# PIC32MZ2064DAS176 device description
Architecture: MIPS; Family: PIC32MZDA; Series: PIC32MZ
Registers are 32-bit, read-write, no defined reset value unless marked. A register's access mark holds for its fields unless they carry their own. Offsets are from the block's base; [hi:lo] are bit positions; 'fields as' and 'values as' point back to an identical list.

## JTAG
Instances: JTAG 0x1f801130 in periph_pb1_std
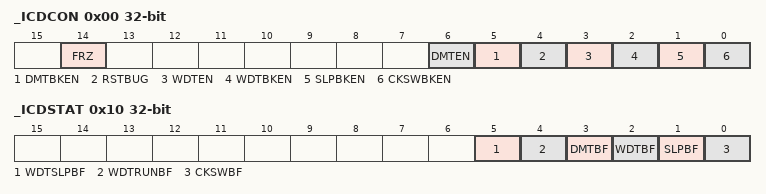
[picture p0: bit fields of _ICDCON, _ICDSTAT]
0x00 _ICDCON
  [14] FRZ, [6] DMTEN, [5] DMTBKEN, [4] RSTBUG, [3] WDTEN, [2] WDTBKEN, [1] SLPBKEN, [0] CKSWBKEN
0x10 _ICDSTAT
  [5] WDTSLPBF, [4] WDTRUNBF, [3] DMTBF, [2] WDTBF, [1] SLPBF, [0] CKSWBF

## OCMP
Instances: OCMP 0x1f844000 in periph_pb3_std
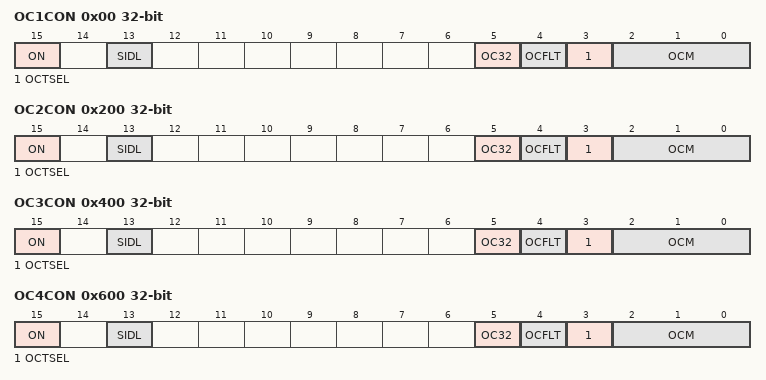
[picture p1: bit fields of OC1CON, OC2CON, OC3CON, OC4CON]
0x00 OC1CON — Output Compare 'x' Control Register
  [15] ON — Output Compare Peripheral On bit
    1=Output Compare peripheral is enabled; 0=Output Compare peripheral is disabled
  [13] SIDL — Stop in Idle Mode bit
    1=Discontinue operation when CPU enters Idle mode; 0=Continue operation in Idle mode
  [5] OC32 — 32-bit Compare Mode bit
    1=OCxR and/or OCxRS<31:0> are used for comparisions to the 32-bit timer source; 0=OCxR and OCxRS<15:0> are used for comparisons to the 16-bit timer source
  [4] OCFLT — PWM Fault Condition Status bit
    1=PWM Fault condition has occurred (cleared in HW only); 0=No PWM Fault condition has occurred
  [3] OCTSEL — Output Compare Timer Select bit
    1=Timery is the clock source for this Output Compare module; 0=Timerx is the clock source for this Output Compare module
  [2:0] OCM — Output Compare Mode Select bits
    7=PWM mode on OCx; Fault pin enabled; 6=PWM mode on OCx; Fault pin diabled; 5=Initialize OCx pin low; generate continious output pulses on OCx pin; 4=Initialize OCx pin low; generate single output pulse on OCx pin; 3=Compare event toggles OCx pin; 2=Initialize OCx pin high; compare event forces OCx pin low; 1=Initialize OCx pin low; compare event forces OCx pin high; 0=Output compare peripheral is disabled but continues to draw current
0x10 OC1R
0x20 OC1RS
0x200 OC2CON — Output Compare 'x' Control Register
  fields as OC1CON
0x210 OC2R
0x220 OC2RS
0x400 OC3CON — Output Compare 'x' Control Register
  fields as OC1CON
0x410 OC3R
0x420 OC3RS
0x600 OC4CON — Output Compare 'x' Control Register
  fields as OC1CON
0x610 OC4R
0x620 OC4RS
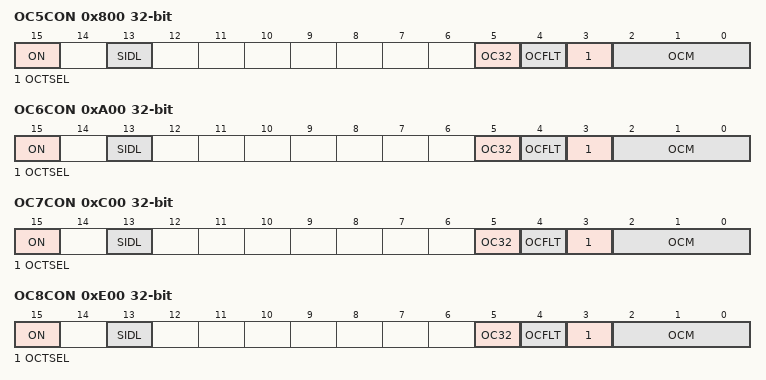
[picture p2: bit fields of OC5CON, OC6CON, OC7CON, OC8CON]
0x800 OC5CON — Output Compare 'x' Control Register
  fields as OC1CON
0x810 OC5R
0x820 OC5RS
0xA00 OC6CON — Output Compare 'x' Control Register
  fields as OC1CON
0xA10 OC6R
0xA20 OC6RS
0xC00 OC7CON — Output Compare 'x' Control Register
  fields as OC1CON
0xC10 OC7R
0xC20 OC7RS
0xE00 OC8CON — Output Compare 'x' Control Register
  fields as OC1CON
0xE10 OC8R
0xE20 OC8RS
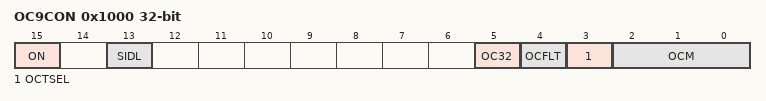
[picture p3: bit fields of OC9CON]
0x1000 OC9CON — Output Compare 'x' Control Register
  fields as OC1CON
0x1010 OC9R
0x1020 OC9RS

## PCACHE
Instances: PCACHE 0x1f8e0000 in periph_indep
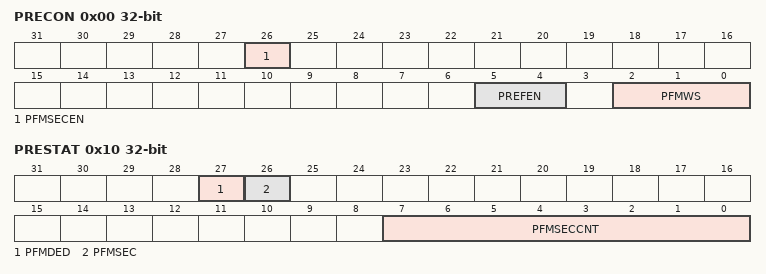
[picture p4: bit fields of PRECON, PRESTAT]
0x00 PRECON — Prefetch Module Control Register
  [26] PFMSECEN — Flash SEC Interrupt Enable bit
    1=Generate an interrupt when the PFMSEC bit (PRESTAT) is set; 0=Do not generate an interrupt when the PFMSEC bit is set
  [5:4] PREFEN — Predictive Prefetch Enable bits
    3=Enable predictive prefetch for any address; 2=Enable predictive prefetch for CPU instructions and CPU data; 1=Enable predictive prefetch for CPU instructions only; 0=Disable predictive prefetch
  [2:0] PFMWS — PFM Access Time Defined in Terms of SYSCLK Wait States bits
    7=Seven Wait states; 6=Six Wait states; 5=Five Wait states; 4=Four Wait states; 3=Three Wait states; 2=Two Wait states; 1=One Wait state; 0=Zero Wait states
0x10 PRESTAT — Prefetch Module Status Register
  [27] PFMDED — Flash Double-bit Error Detected Status bit
    1=A DED error has occurred; 0=A DED error has not occurred
  [26] PFMSEC — Flash Single-bit Error Corrected Status bit
    1=A SEC error occurred when PFMSECCNT was equal to zero; 0=A SEC error has not occurred
  [7:0] PFMSECCNT — Flash SEC Count bits
    255=SEC count of 255; 254=SEC count of 254; 1=SEC count of 1; 0=SEC count of 0

## RNG
Instances: RNG 0x1f8e6000 in periph_indep
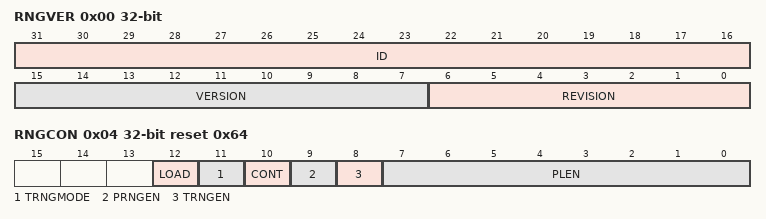
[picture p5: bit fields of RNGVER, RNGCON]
0x00 RNGVER ro — Random Number Generator Version Register
  [31:16] ID, [15:7] VERSION, [6:0] REVISION
0x04 RNGCON reset 0x64 — Random Number Generator Control Register
  [12] LOAD
  [11] TRNGMODE — TRNG Mode Selection bit
    1=Use ring oscillators with bias corrector; 0=Use ring oscillators with XOR tree
  [10] CONT — PRNG Number Shift Enable bit
    1=The PRNG random number is shifted every cycle; 0=The PRNG random number is shifted when the previous value is removed
  [9] PRNGEN — PRNG Operation Enable bit
    1=PRNG operation is enabled; 0=PRNG operation is not enabled
  [8] TRNGEN — TRNG Operation Enable bit
    1=TRNG operation is enabled; 0=TRNG operation is not enabled
  [7:0] PLEN — PRNG Polynomial Length bits
0x08 RNGPOLY1 reset 0xFFFF0000 — Random Number Generator Polynomial Register x (x = 1 or 2
  [31:0] POLY
0x0C RNGPOLY2 reset 0xFFFF0000 — Random Number Generator Polynomial Register x (x = 1 or 2)
  [31:0] POLY
0x10 RNGNUMGEN1 reset 0xFFFFFFFF — Random Number Generator Register x (x = 1 or 2)
  [31:0] RNG
0x14 RNGNUMGEN2 reset 0xFFFFFFFF — Random Number Generator Register x (x = 1 or 2)
  [31:0] RNG
0x18 RNGSEED1 ro — True Random Number Generator Seed Register x (x = 1 or 2
  [31:0] SEED
0x1C RNGSEED2 ro — True Random Number Generator Seed Register x (x = 1 or 2
  [31:0] SEED
0x20 RNGCNT — True Random Number Generator Count Register
  [6:0] RCNT

## Notices in the file
Copyright (c) 2017 Microchip Technology Inc.
SPDX-License-Identifier: Apache-2.0
Licensed under the Apache License, Version 2.0 (the "License");
you may not use this file except in compliance with the License.
You may obtain a copy of the License at
http://www.apache.org/licenses/LICENSE-2.0
Unless required by applicable law or agreed to in writing, software
distributed under the License is distributed on an "AS IS" BASIS,
WITHOUT WARRANTIES OR CONDITIONS OF ANY KIND, either express or implied.
See the License for the specific language governing permissions and
limitations under the License.
